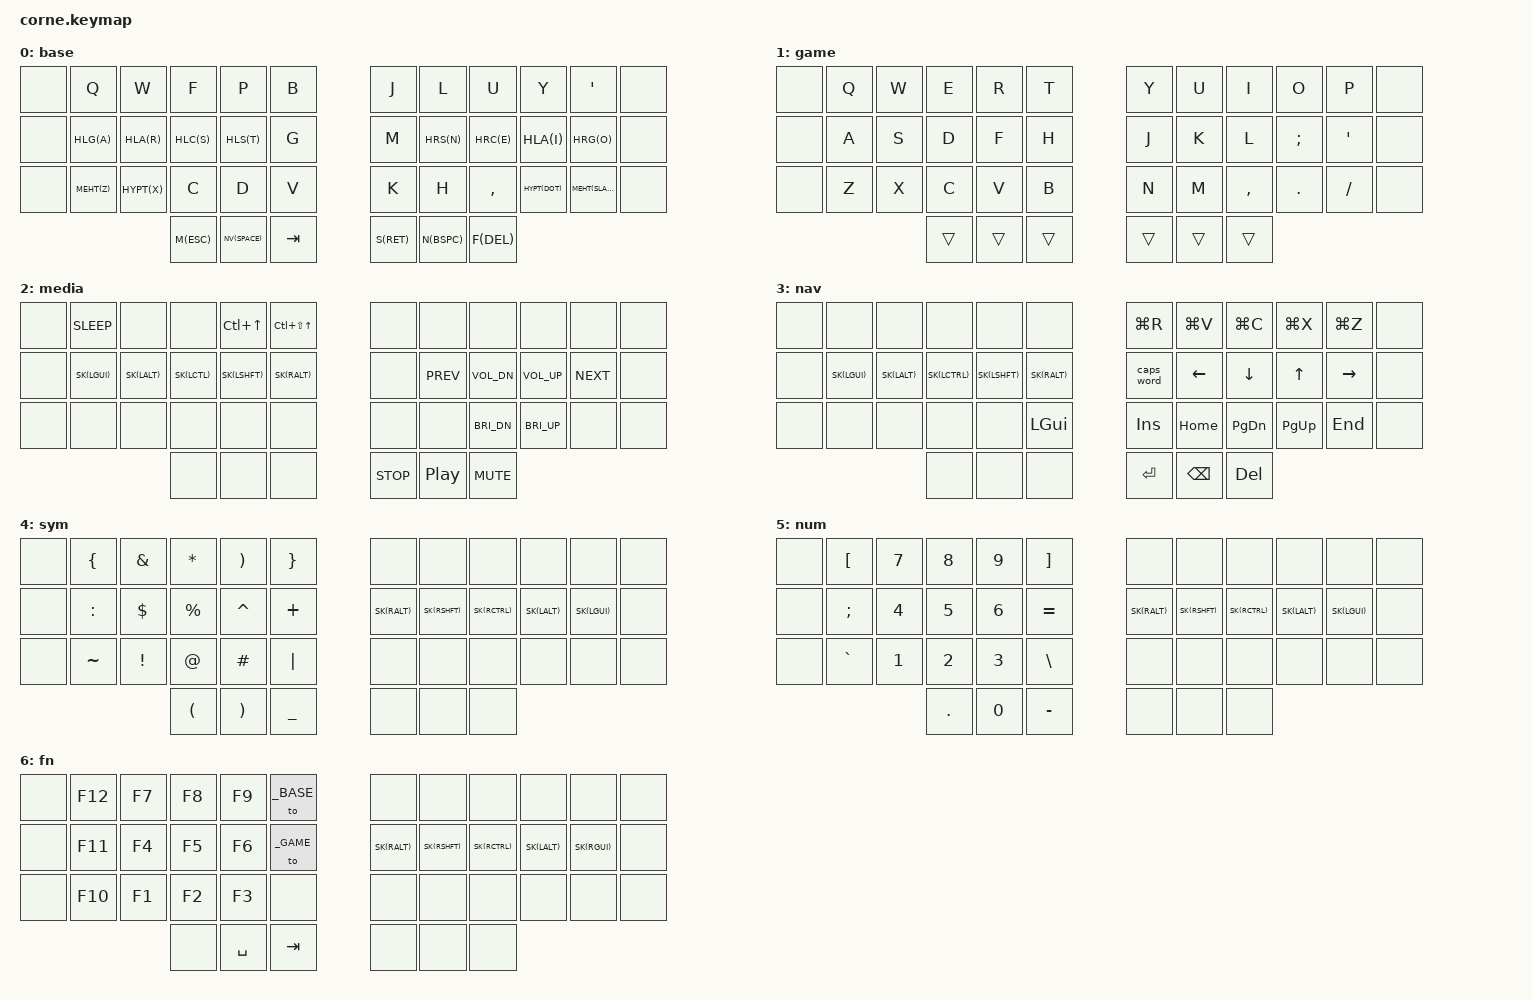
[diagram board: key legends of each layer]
/*
 * Copyright (c) 2020 The ZMK Contributors
 *
 * SPDX-License-Identifier: MIT
 */

#include <behaviors.dtsi>
#include <dt-bindings/zmk/bt.h>
#include <dt-bindings/zmk/keys.h>

// Convenience maps
#define XXX &none // No-op key
#define UUU &none // Unused key
#define ___ &trans // Transparent key

// Layers
#define _BASE 0
#define _GAME 1
#define _MEDIA 2
#define _NAV 3
#define _SYM 5
#define _NUM 6
#define _FN 7

// Sticky key
#define SK(key) &sk key

// Layer Toggles
#define _TB &to _BASE
#define _TG &to _GAME

// Home-row Mods
#define HLA(key) &hm LALT key
#define HLG(key) &hm LGUI key
#define HRG(key) &hm RGUI key
#define HLC(key) &hm LCTRL key
#define HRC(key) &hm RCTRL key
#define HLS(key) &hm LSHFT key
#define HRS(key) &hm RSHFT key

// Mod-taps
#define MEHT(key) &mt LC(LS(LALT)) key
#define HYPT(key) &mt LC(LS(LA(LGUI))) key

// Layer Taps
#define _M(key) &lt _MEDIA key
#define _NV(key) &lt _NAV key
#define _S(key) &lt _SYM key
#define _N(key) &lt _NUM key
#define _F(key) &lt _FN key

&mt {
    flavor = "tap-preferred";
    tapping_term_ms = <200>;
};

/* Layer template
layer {
    label = "name";
    bindings = <
    //┌─────┬─────────────┬─────────────┬─────────────┬─────────────┬─────────────┐  ┌─────────────┬─────────────┬─────────────┬─────────────┬─────────────┬─────┐
    //│     │             │             │             │             │             │  │             │             │             │             │             │     │
        UUU   XXX           XXX           XXX           XXX           XXX              XXX           XXX           XXX           XXX           XXX           UUU
    //├─────┼─────────────┼─────────────┼─────────────┼─────────────┼─────────────┤  │─────────────┼─────────────┼─────────────┼─────────────┼─────────────┼─────┤
    //│     │             │             │             │             │             │  │             │             │             │             │             │     │
        UUU   XXX           XXX           XXX           XXX           XXX              XXX           XXX           XXX           XXX           XXX           UUU
    //├─────┼─────────────┼─────────────┼─────────────┼─────────────┼─────────────┤  ├─────────────┼─────────────┼─────────────┼─────────────┼─────────────┼─────┤
    //│     │             │             │             │             │             │  │             │             │             │             │             │     │
        UUU   XXX           XXX           XXX           XXX           XXX              XXX           XXX           XXX           XXX           XXX           UUU
    //└─────────────────────────────────┼─────────────┼─────────────┼─────────────┤  ├─────────────┼─────────────┼─────────────┼─────────────────────────────────┤
    //                                  │             │             │             │  │             │             │             │
                                          XXX           XXX           XXX              XXX           XXX           XXX
    //                                  └─────────────┴─────────────┴─────────────┘  └─────────────┴─────────────┴─────────────┘
    >;
};
*/

/* clang-format off */
/ {
    behaviors {
        hm: homerow_mods {
            compatible = "zmk,behavior-hold-tap";
            label = "HOMEROW_MODS";
            #binding-cells = <2>;
            tapping-term-ms = <200>;
            quick_tap_ms = <0>;
            flavor = "tap-preferred";
            bindings = <&kp>, <&kp>;
        };
    };

    keymap {
        compatible = "zmk,keymap";

        base {
            label = "base";
            bindings = <
            // ┌──────┬─────────────┬─────────────┬─────────────┬─────────────┬─────────────┐  ┌─────────────┬─────────────┬─────────────┬─────────────┬─────────────┬──────┐
            // │      │ Q           │ W           │ F           │ P           │ B           │  │ J           │ L           │ U           │ Y           │ '           │      │
                 UUU    &kp Q         &kp W         &kp F         &kp P         &kp B            &kp J         &kp L         &kp U         &kp Y         &kp SQT       UUU
            // ├──────┼─────────────┼─────────────┼─────────────┼─────────────┼─────────────┤  │─────────────┼─────────────┼─────────────┼─────────────┼─────────────┼──────┤
            // │      │ A 󰘳         │ R 󰘵         │ S 󰘴         │ T 󰘶         │ G           │  │ M           │ N 󰘶         │ E 󰘴         │ I 󰘵         │ O 󰘳         │      │
                 UUU    HLG(A)        HLA(R)        HLC(S)        HLS(T)        &kp G            &kp M         HRS(N)        HRC(E)        HLA(I)        HRG(O)        UUU
            // ├──────┼─────────────┼─────────────┼─────────────┼─────────────┼─────────────┤  ├─────────────┼─────────────┼─────────────┼─────────────┼─────────────┼──────┤
            // │      │ Z 󰘴󰘶󰘵       │ X 󰘴󰘶󰘵󰘳      │ C           │ D           │ V           │  │ K           │ H           │ ,           │ . 󰘴󰘶󰘵󰘳      │ / 󰘴󰘶󰘵       │      │
                 UUU    MEHT(Z)       HYPT(X)       &kp C         &kp D         &kp V            &kp K         &kp H         &kp COMMA     HYPT(DOT)     MEHT(SLASH)   UUU
            // └──────────────────────────────────┼─────────────┼─────────────┼─────────────┤  ├─────────────┼─────────────┼─────────────┼──────────────────────────────────┤
            //                                    │ Esc _MEDIA  │ 󱁐 _NAV      │            │  │ ⏎ _SYM      │ 󰭜 _NUM      │ 󰹿 _FN       │
                                                    _M(ESC)       _NV(SPACE)    &kp TAB          _S(RET)       _N(BSPC)      _F(DEL)
            //                                    └─────────────┴─────────────┴─────────────┘  └─────────────┴─────────────┴─────────────┘
            >;
        };

        game {
            label = "game";
            bindings = <
            // ┌──────┬─────────────┬─────────────┬─────────────┬─────────────┬─────────────┐  ┌─────────────┬─────────────┬─────────────┬─────────────┬─────────────┬──────┐
            // │      │ Q           │ W           │ E           │ R           │ T           │  │ Y           │ U           │ I           │ O           │ P           │      │
                 UUU    &kp Q         &kp W         &kp E         &kp R         &kp T            &kp Y         &kp U         &kp I         &kp O         &kp P         UUU
            // ├──────┼─────────────┼─────────────┼─────────────┼─────────────┼─────────────┤  │─────────────┼─────────────┼─────────────┼─────────────┼─────────────┼──────┤
            // │      │ A           │ S           │ D           │ F           │ H           │  │ J           │ K           │ L           │ ;           │ '           │      │
                 UUU    &kp A         &kp S         &kp D         &kp F         &kp H            &kp J         &kp K         &kp L         &kp SEMI      &kp SQT       UUU
            // ├──────┼─────────────┼─────────────┼─────────────┼─────────────┼─────────────┤  ├─────────────┼─────────────┼─────────────┼─────────────┼─────────────┼──────┤
            // │      │ Z           │ X           │ C           │ V           │ B           │  │ N           │ M           │ , <         │ . >         │ / ?         │      │
                 UUU    &kp Z         &kp X         &kp C         &kp V         &kp B            &kp N         &kp M         &kp COMMA     &kp DOT       &kp SLASH     UUU
            // └──────────────────────────────────┼─────────────┼─────────────┼─────────────┤  ├─────────────┼─────────────┼─────────────┼──────────────────────────────────┤
            //                                    │ Esc _MEDIA  │ 󱁐 _NAV      │            │  │ ⏎ _SYM      │ 󰭜 _NUM      │ 󰹿 _FN       │
                                                    ___           ___           ___              ___           ___           ___
            //                                    └─────────────┴─────────────┴─────────────┘  └─────────────┴─────────────┴─────────────┘
            >;
        };

        media {
            label = "media";
            bindings = <
            // ┌──────┬─────────────┬─────────────┬─────────────┬─────────────┬─────────────┐  ┌─────────────┬─────────────┬─────────────┬─────────────┬─────────────┬──────┐
            // │      │ Sleep       │             │             │ Mission Ctl │ Launchpad   │  │             │             │             │             │             │      │
                 UUU    &kp C_SLEEP   XXX           XXX           &kp LC(UP)    &kp LC(LS(UP))   XXX           XXX           XXX           XXX           XXX           UUU
            // ├──────┼─────────────┼─────────────┼─────────────┼─────────────┼─────────────┤  ├─────────────┼─────────────┼─────────────┼─────────────┼─────────────┼──────┤
            // │      │ 󰘳           │ 󰘵           │ 󰘴           │ 󰘶           │ AltGr       │  │             │ 󰒮           │            │            │ 󰒭           │      │
                 UUU    SK(LGUI)      SK(LALT)      SK(LCTL)      SK(LSHFT)     SK(RALT)         XXX           &kp C_PREV    &kp C_VOL_DN  &kp C_VOL_UP  &kp C_NEXT    UUU
            // ├──────┼─────────────┼─────────────┼─────────────┼─────────────┼─────────────┤  ├─────────────┼─────────────┼─────────────┼─────────────┼─────────────┼──────┤
            // │      │             │             │             │             │             │  │             │             │ 🔅          │ 🔆          │             │      │
                 UUU    XXX           XXX           XXX           XXX           XXX              XXX           XXX           &kp C_BRI_DN  &kp C_BRI_UP  XXX           UUU
            // └──────────────────────────────────┼─────────────┼─────────────┼─────────────┤  ├─────────────┼─────────────┼─────────────┼─────────────┴────────────────────┘
            //                                    │ *           │             │             │  │            │ 󰐎           │            │
                                                    XXX           XXX           XXX              &kp C_STOP    &kp C_PP      &kp C_MUTE
            //                                    └─────────────┴─────────────┴─────────────┘  └─────────────┴─────────────┴─────────────┘
            >;
        };

        nav {
            label = "nav";
            bindings = <
            // ┌──────┬─────────────┬─────────────┬─────────────┬─────────────┬─────────────┐  ┌─────────────┬─────────────┬─────────────┬─────────────┬─────────────┬──────┐
            // │      │             │             │             │             │             │  │ Redo        │ Paste       │ Copy        │ Cut         │ Undo        │      │
                 UUU    XXX           XXX           XXX           XXX           XXX              &kp LG(R)     &kp LG(V)     &kp LG(C)      &kp LG(X)     &kp LG(Z)     UUU
            // ├──────┼─────────────┼─────────────┼─────────────┼─────────────┼─────────────┤  ├─────────────┼─────────────┼─────────────┼─────────────┼─────────────┼──────┤
            // │      │ 󰘳           │ 󰘵           │ 󰘴           │ 󰘶           │ AltGr       │  │ Caps Toggle │ ←           │ ↓           │ ↑           │ →           │      │
                 UUU    SK(LGUI)      SK(LALT)      SK(LCTRL)     SK(LSHFT)     SK(RALT)         &caps_word    &kp LEFT      &kp DOWN      &kp UP        &kp RIGHT     UUU
            // ├──────┼─────────────┼─────────────┼─────────────┼─────────────┼─────────────┤  ├─────────────┼─────────────┼─────────────┼─────────────┼─────────────┼──────┤
            // │      │             │             │             │             │ 󰘳           │  │ Insert      │ ⇱           │ ⇟           │ ⇞           │ ⇲           │      │
                 UUU    XXX           XXX           XXX           XXX           &kp LGUI         &kp INS       &kp HOME      &kp PG_DN     &kp PG_UP     &kp END       UUU
            // └──────────────────────────────────┼─────────────┼─────────────┼─────────────┤  ├─────────────┼─────────────┼─────────────┼─────────────┴────────────────────┘
            //                                    │             │ *           │             │  │ ⏎           │ 󰹿           │ ⏎ _FN       │
                                                    XXX           XXX           XXX              &kp RET       &kp BSPC      &kp DEL
            //                                    └─────────────┴─────────────┴─────────────┘  └─────────────┴─────────────┴─────────────┘
            >;
        };

        sym {
            label = "sym";
            bindings = <
            // ┌──────┬─────────────┬─────────────┬─────────────┬─────────────┬─────────────┐  ┌─────────────┬─────────────┬─────────────┬─────────────┬─────────────┬──────┐
            // │      │ {           │ &           │ *           │ )           │ }           │  │             │             │             │             │             │      │
                 UUU    &kp LBRC      &kp AMPS      &kp ASTRK     &kp RPAR      &kp RBRC         XXX           XXX           XXX           XXX           XXX           UUU
            // ├──────┼─────────────┼─────────────┼─────────────┼─────────────┼─────────────┤  ├─────────────┼─────────────┼─────────────┼─────────────┼─────────────┼──────┤
            // │      │ :           │ $           │ %           │ ^           │ +           │  │ AltGr       │ 󰘶           │ 󰘴           │ 󰘵           │ 󰘳           │      │
                 UUU    &kp COLON     &kp DLLR      &kp PRCNT     &kp CARET     &kp PLUS         SK(RALT)      SK(RSHFT)     SK(RCTRL)     SK(LALT)      SK(LGUI)      UUU
            // ├──────┼─────────────┼─────────────┼─────────────┼─────────────┼─────────────┤  ├─────────────┼─────────────┼─────────────┼─────────────┼─────────────┼──────┤
            // │      │ ~           │ !           │ @           │ #           │ |           │  │             │             │             │             │             │      │
                 UUU    &kp TILDE     &kp EXCL      &kp AT        &kp HASH      &kp PIPE         XXX           XXX           XXX           XXX           XXX           UUU
            // └──────────────────────────────────┼─────────────┼─────────────┼─────────────┤  ├─────────────┼─────────────┼─────────────┼─────────────┴────────────────────┘
            //                                    │ (           │ )           │ _           │  │ *           │             │             │
                                                    &kp LPAR      &kp RPAR      &kp UNDER        XXX           XXX           XXX
            //                                    └─────────────┴─────────────┴─────────────┘  └─────────────┴─────────────┴─────────────┘
            >;
        };

        num {
            label = "num";
            bindings = <
            // ┌──────┬─────────────┬─────────────┬─────────────┬─────────────┬─────────────┐  ┌─────────────┬─────────────┬─────────────┬─────────────┬─────────────┬──────┐
            // │      │ [ {         │ 7 &         │ 8 *         │ 9 )         │ ] }         │  │             │             │             │             │             │      │
                 UUU    &kp LBKT      &kp N7        &kp N8        &kp N9        &kp RBKT         XXX           XXX           XXX           XXX           XXX           UUU
            // ├──────┼─────────────┼─────────────┼─────────────┼─────────────┼─────────────┤  ├─────────────┼─────────────┼─────────────┼─────────────┼─────────────┼──────┤
            // │      │ ; :         │ 4 $         │ 5 %         │ 6 ^         │ = +         │  │ AltGr       │ 󰘶           │ 󰘴           │ 󰘵           │ 󰘳           │      │
                 UUU    &kp SEMI      &kp N4        &kp N5        &kp N6        &kp EQUAL        SK(RALT)      SK(RSHFT)     SK(RCTRL)     SK(LALT)      SK(LGUI)      UUU
            // ├──────┼─────────────┼─────────────┼─────────────┼─────────────┼─────────────┤  ├─────────────┼─────────────┼─────────────┼─────────────┼─────────────┼──────┤
            // │      │ ` ~         │ 1 !         │ 2 @         │ 3 #         │ \ |         │  │             │             │             │             │             │      │
                 UUU    &kp GRAVE     &kp N1        &kp N2        &kp N3        &kp BSLH         XXX           XXX           XXX           XXX           XXX           UUU
            // └──────────────────────────────────┼─────────────┼─────────────┼─────────────┤  ├─────────────┼─────────────┼─────────────┼─────────────┴────────────────────┘
            //                                    │ . >         │ 0 )         │ - _         │  │             │ *           │             │
                                                    &kp DOT       &kp N0        &kp MINUS        XXX           XXX           XXX
            //                                    └─────────────┴─────────────┴─────────────┘  └─────────────┴─────────────┴─────────────┘
            >;
        };

        fn {
            label = "fn";
            bindings = <
            // ┌──────┬─────────────┬─────────────┬─────────────┬─────────────┬─────────────┐  ┌─────────────┬─────────────┬─────────────┬─────────────┬─────────────┬──────┐
            // │      │ F12         │ F7          │ F8          │ F9          │ _BASE       │  │             │             │             │             │             │      │
                 UUU    &kp F12       &kp F7        &kp F8        &kp F9        _TB              XXX           XXX           XXX           XXX           XXX           UUU
            // ├──────┼─────────────┼─────────────┼─────────────┼─────────────┼─────────────┤  ├─────────────┼─────────────┼─────────────┼─────────────┼─────────────┼──────┤
            // │      │ F11         │ F4          │ F5          │ F6          │ _GAME       │  │ AltGr       │ 󰘶           │ 󰘴           │ 󰘵           │ 󰘳           │      │
                 UUU    &kp F11       &kp F4        &kp F5        &kp F6        _TG              SK(RALT)      SK(RSHFT)     SK(RCTRL)     SK(LALT)      SK(RGUI)      UUU
            // ├──────┼─────────────┼─────────────┼─────────────┼─────────────┼─────────────┤  ├─────────────┼─────────────┼─────────────┼─────────────┼─────────────┼──────┤
            // │      │ F10         │ F1          │ F2          │ F3          │             │  │             │             │             │             │             │      │
                 UUU    &kp F10       &kp F1        &kp F2        &kp F3        XXX              XXX           XXX           XXX           UUU           UUU           UUU
            // ├──────┼─────────────┼─────────────┼─────────────┼─────────────┼─────────────┤  ├─────────────┼─────────────┼─────────────┼─────────────┴────────────────────┘
            //                                    │             │ 󱁐           │            │  │             │             │ *           │
                                                    XXX           &kp SPACE     &kp TAB           XXX           XXX           XXX
            //                                    └─────────────┴─────────────┴─────────────┘  └─────────────┴─────────────┴─────────────┘
            >;
        };
    };
};
/* clang-format on */
